# MSS_GIO register map
Vendor: Texas Instruments
Peripheral module from a debugger description file (folder awr29xx).
Registers are 32-bit, read-write, no defined reset value unless marked. A register's access mark holds for its fields unless they carry their own. Offsets are as the file gives them; lines under a group give offsets from that group; [hi:lo] are bit positions; {n}, {i} and the like mark numbered series; 'fields as' and 'values as' point back to an identical list; <NAME> marks a mode.

## MSS_GIO
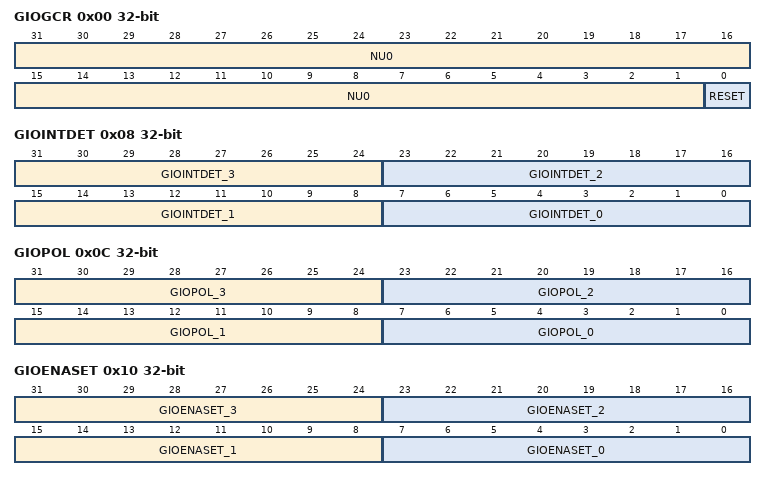
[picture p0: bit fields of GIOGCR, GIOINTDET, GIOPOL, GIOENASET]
0x00 GIOGCR — GIO reset
  [31:1] NU0 — Reserved
  [0] RESET — GIO reset
0x04 GIOPWDN 33-bit — GIO power down mode register
  [32:1] NU — Reserved
  [0] GIOPWDN — Writing to the GIOPWDN bit is only allowed in privilege mode. Reading of the GIOPWDN bit is allowed in all modes. Privilege mode (write): 0 = Normal operation; clocks enabled to GIO module 1 = Power-down mode User mode (write): Writes have no effect in user mode. User or privilege mode (read): 0 = Normal operation; clocks enabled to GIO module 1 = Power-down mode
0x08 GIOINTDET — Interrupt detection select for pins [0:1] GIO[7:0].
  [31:24] GIOINTDET_3 — Interrupt detection select for pins GIOD[7:0].
  [23:16] GIOINTDET_2 — Interrupt detection select for pins GIOC[7:0].
  [15:8] GIOINTDET_1 — Interrupt detection select for pins GIOB[7:0].
  [7:0] GIOINTDET_0 — Interrupt detection select for pins GIOA[7:0].
0x0C GIOPOL — Interrupt polarity select for pins [0:1] GIO[7:0].
  [31:24] GIOPOL_3 — Interrupt polarity select for pins GIOD[7:0]
  [23:16] GIOPOL_2 — Interrupt polarity select for pins GIOC[7:0]
  [15:8] GIOPOL_1 — Interrupt polarity select for pins GIOB[7:0]
  [7:0] GIOPOL_0 — Interrupt polarity select for pins GIOA[7:0]
0x10 GIOENASET — Interrupt enable for pins [0:1] GIO[7:0].
  [31:24] GIOENASET_3 — Interrupt enable for pins GIOD [7:0]
  [23:16] GIOENASET_2 — Interrupt enable for pins GIOC [7:0]
  [15:8] GIOENASET_1 — Interrupt enable for pins GIOB [7:0]
  [7:0] GIOENASET_0 — Interrupt enable for pins GIOA [7:0]
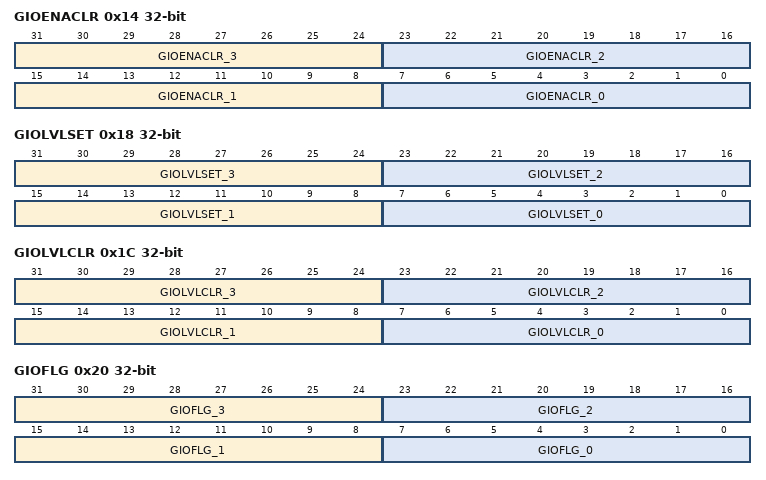
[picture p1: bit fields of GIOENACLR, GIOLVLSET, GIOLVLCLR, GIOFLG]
0x14 GIOENACLR — Interrupt enable for pins [0:1] GIO[7:0].
  [31:24] GIOENACLR_3 — Interrupt enable for pins GIOD [7:0]
  [23:16] GIOENACLR_2 — Interrupt enable for pins GIOC [7:0]
  [15:8] GIOENACLR_1 — Interrupt enable for pins GIOB [7:0]
  [7:0] GIOENACLR_0 — Interrupt enable for pins GIOA [7:0]
0x18 GIOLVLSET — GIO high priority interrupt for pins [0:1] GIO[7:0].
  [31:24] GIOLVLSET_3 — GIO high priority interrupt for pins GIOD[7:0]
  [23:16] GIOLVLSET_2 — GIO high priority interrupt for pins GIOC[7:0]
  [15:8] GIOLVLSET_1 — GIO high priority interrupt for pins GIOB[7:0]
  [7:0] GIOLVLSET_0 — GIO high priority interrupt for pins GIOA[7:0]
0x1C GIOLVLCLR — GIO low priority interrupt for pins [0:1] GIO[7:0].
  [31:24] GIOLVLCLR_3 — GIO low priority interrupt for pins GIOD[7:0]
  [23:16] GIOLVLCLR_2 — GIO low priority interrupt for pins GIOC[7:0]
  [15:8] GIOLVLCLR_1 — GIO low priority interrupt for pins GIOB[7:0]
  [7:0] GIOLVLCLR_0 — GIO low priority interrupt for pins GIOA[7:0]
0x20 GIOFLG — GIO flag for pins [0:1] GIO[7:0].
  [31:24] GIOFLG_3 — GIO flag for pins GIOD[7:0]
  [23:16] GIOFLG_2 — GIO flag for pins GIOC[7:0]
  [15:8] GIOFLG_1 — GIO flag for pins GIOB[7:0]
  [7:0] GIOFLG_0 — GIO flag for pins GIOA[7:0]
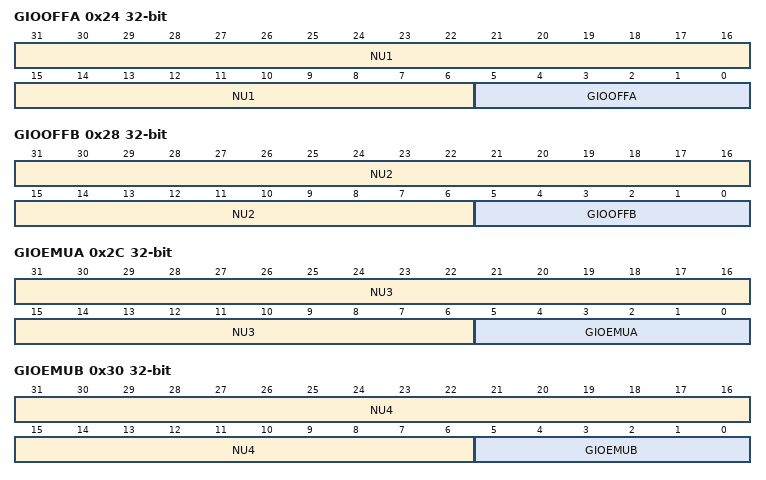
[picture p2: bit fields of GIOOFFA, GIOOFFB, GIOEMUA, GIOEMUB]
0x24 GIOOFFA — Index bits for currently pending high-priority interrupt Register A
  [31:6] NU1 — Reserved
  [5:0] GIOOFFA — Index bits for currently pending high-priority interrupt Register A
0x28 GIOOFFB — Index bits for currently pending high-priority interrupt Register B
  [31:6] NU2 — Reserved
  [5:0] GIOOFFB — Index bits for currently pending high-priority interrupt Register B
0x2C GIOEMUA — GIO emulation register A
  [31:6] NU3 — Reserved
  [5:0] GIOEMUA — GIO emulation register A
0x30 GIOEMUB — GIO emulation register B
  [31:6] NU4 — Reserved
  [5:0] GIOEMUB — GIO emulation register B
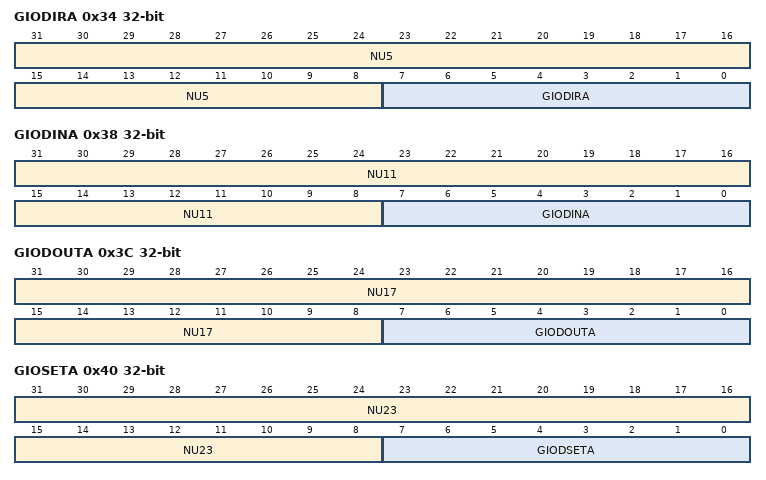
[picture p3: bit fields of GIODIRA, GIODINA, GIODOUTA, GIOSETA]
0x34 GIODIRA — GIO data direction of pins in Port A
  [31:8] NU5 — Reserved
  [7:0] GIODIRA — GIO data direction of pins in Port A
0x38 GIODINA — GIO data input for pins in port A
  [31:8] NU11 — Reserved
  [7:0] GIODINA — GIO data input for pins in port A
0x3C GIODOUTA — GIO data output for pins in port A
  [31:8] NU17 — Reserved
  [7:0] GIODOUTA — GIO data output for pins in port A
0x40 GIOSETA — GIO data set for port A
  [31:8] NU23 — Reserved
  [7:0] GIODSETA — GIO data set for port A
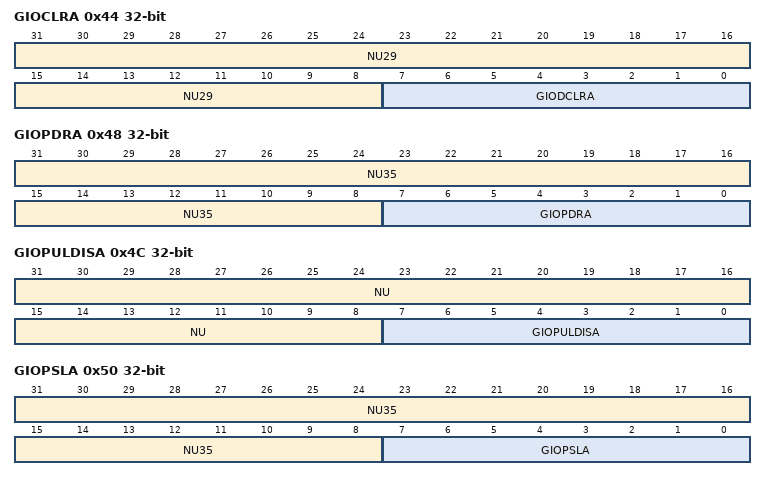
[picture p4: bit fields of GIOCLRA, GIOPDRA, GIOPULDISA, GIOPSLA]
0x44 GIOCLRA — GIO data clear for port A
  [31:8] NU29 — Reserved
  [7:0] GIODCLRA — GIO data clear for port A
0x48 GIOPDRA — GIO open drain for port A
  [31:8] NU35 — Reserved
  [7:0] GIOPDRA — GIO open drain for port A
0x4C GIOPULDISA — GIO pul disable for port A
  [31:8] NU — Reserved
  [7:0] GIOPULDISA — GIO pull disable for port A
0x50 GIOPSLA — GIO pul select for port A
  [31:8] NU35 — Reserved
  [7:0] GIOPSLA — GIO pull select for port A
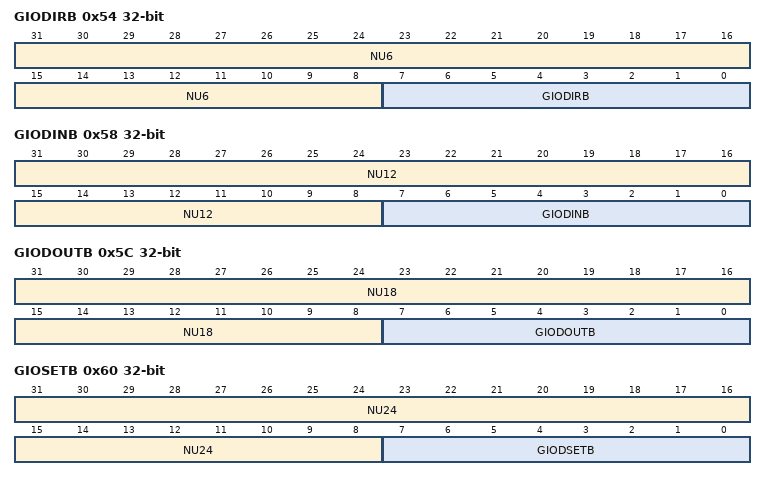
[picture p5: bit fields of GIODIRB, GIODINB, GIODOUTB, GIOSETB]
0x54 GIODIRB — GIO data direction of pins in Port B
  [31:8] NU6 — Reserved
  [7:0] GIODIRB — GIO data direction of pins in Port B
0x58 GIODINB — GIO data input for pins in port B
  [31:8] NU12 — Reserved
  [7:0] GIODINB — GIO data input for pins in port B
0x5C GIODOUTB — GIO data output for pins in port B
  [31:8] NU18 — Reserved
  [7:0] GIODOUTB — GIO data output for pins in port B
0x60 GIOSETB — GIO data set for port B
  [31:8] NU24 — Reserved
  [7:0] GIODSETB — GIO data set for port B
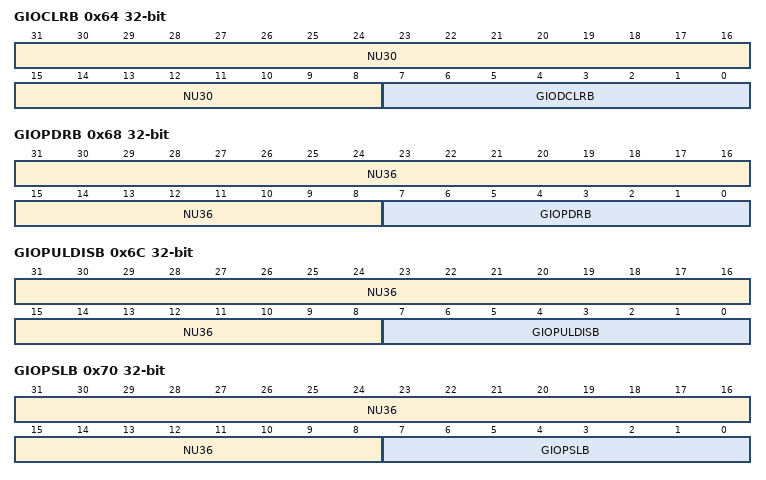
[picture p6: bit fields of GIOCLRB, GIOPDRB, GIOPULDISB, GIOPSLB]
0x64 GIOCLRB — GIO data clear for port B
  [31:8] NU30 — Reserved
  [7:0] GIODCLRB — GIO data clear for port B
0x68 GIOPDRB — GIO open drain for port B
  [31:8] NU36 — Reserved
  [7:0] GIOPDRB — GIO open drain for port B
0x6C GIOPULDISB — GIO pul disable for port B
  [31:8] NU36 — Reserved
  [7:0] GIOPULDISB — GIO pull disable for port B
0x70 GIOPSLB — GIO pul select for port B
  [31:8] NU36 — Reserved
  [7:0] GIOPSLB — GIO pull select for port B
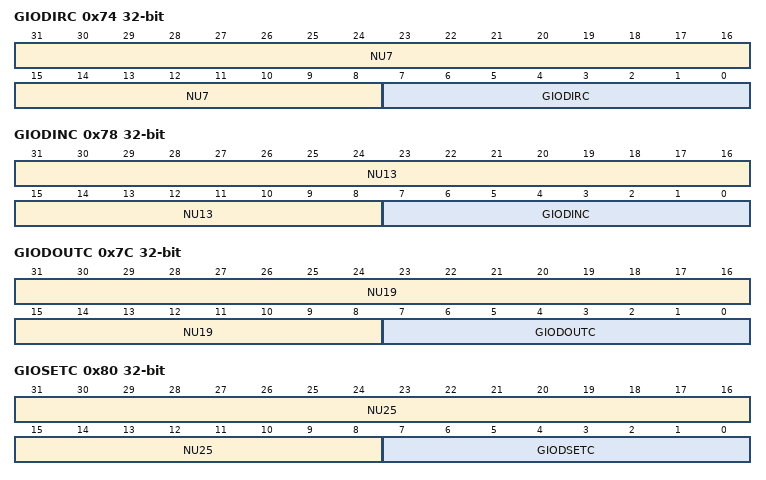
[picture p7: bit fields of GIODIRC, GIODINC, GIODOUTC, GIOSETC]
0x74 GIODIRC — GIO data direction of pins in Port C
  [31:8] NU7 — Reserved
  [7:0] GIODIRC — GIO data direction of pins in Port C
0x78 GIODINC — GIO data input for pins in port C
  [31:8] NU13 — Reserved
  [7:0] GIODINC — GIO data input for pins in port C
0x7C GIODOUTC — GIO data output for pins in port C
  [31:8] NU19 — Reserved
  [7:0] GIODOUTC — GIO data output for pins in port C
0x80 GIOSETC — GIO data set for port C
  [31:8] NU25 — Reserved
  [7:0] GIODSETC — GIO data set for port C
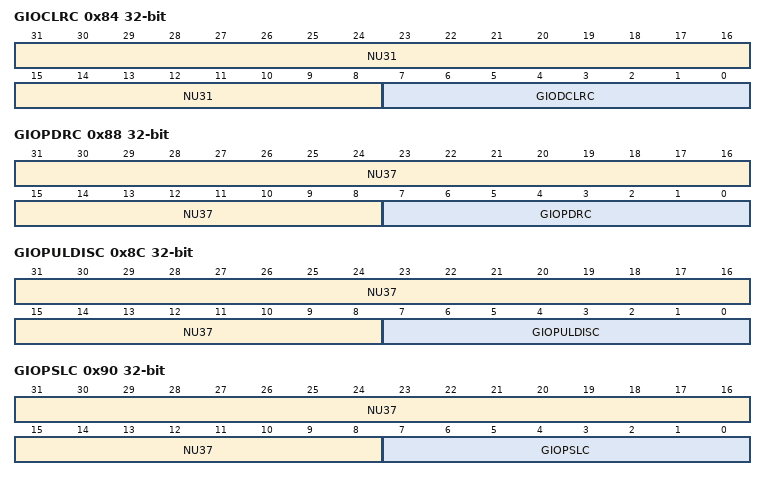
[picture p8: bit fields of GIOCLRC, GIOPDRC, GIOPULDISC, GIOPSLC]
0x84 GIOCLRC — GIO data clear for port C
  [31:8] NU31 — Reserved
  [7:0] GIODCLRC — GIO data clear for port C
0x88 GIOPDRC — GIO open drain for port C
  [31:8] NU37 — Reserved
  [7:0] GIOPDRC — GIO open drain for port C
0x8C GIOPULDISC — GIO pul disable for port C
  [31:8] NU37 — Reserved
  [7:0] GIOPULDISC — GIO pull disable for port C
0x90 GIOPSLC — GIO pul select for port C
  [31:8] NU37 — Reserved
  [7:0] GIOPSLC — GIO pull select for port C
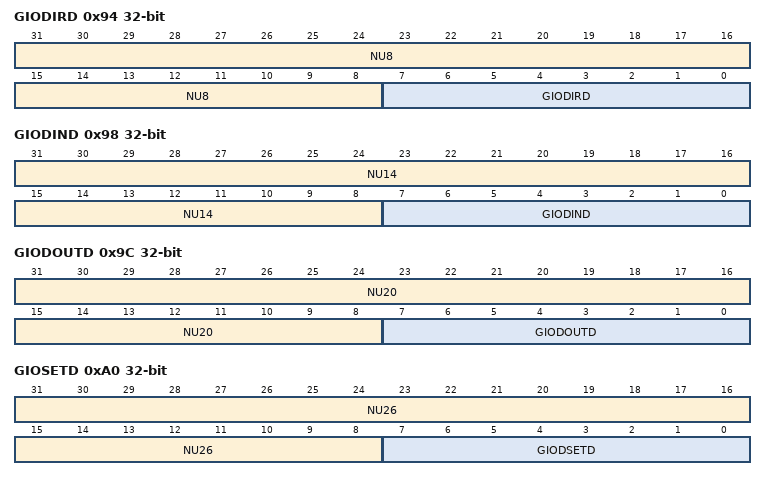
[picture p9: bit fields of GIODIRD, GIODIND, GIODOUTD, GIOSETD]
0x94 GIODIRD — GIO data direction of pins in Port D
  [31:8] NU8 — Reserved
  [7:0] GIODIRD — GIO data direction of pins in Port D
0x98 GIODIND — GIO data input for pins in port D
  [31:8] NU14 — Reserved
  [7:0] GIODIND — GIO data input for pins in port D
0x9C GIODOUTD — GIO data output for pins in port D
  [31:8] NU20 — Reserved
  [7:0] GIODOUTD — GIO data output for pins in port D
0xA0 GIOSETD — GIO data set for port D
  [31:8] NU26 — Reserved
  [7:0] GIODSETD — GIO data set for port D
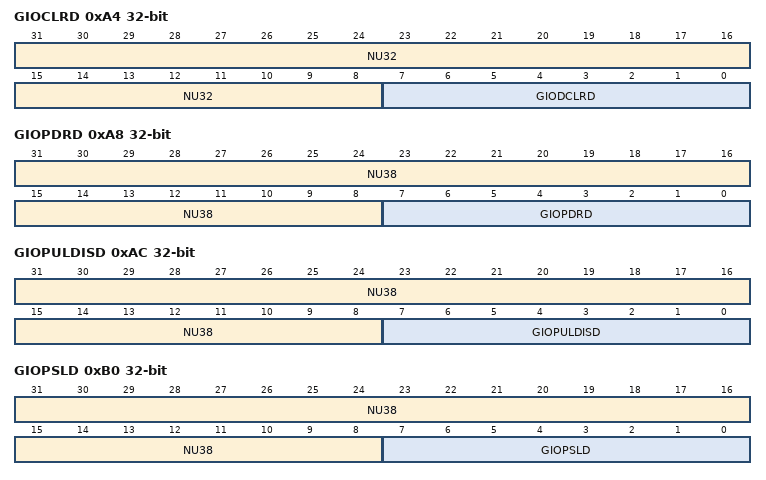
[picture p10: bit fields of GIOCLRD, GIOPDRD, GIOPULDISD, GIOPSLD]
0xA4 GIOCLRD — GIO data clear for port D
  [31:8] NU32 — Reserved
  [7:0] GIODCLRD — GIO data clear for port D
0xA8 GIOPDRD — GIO open drain for port D
  [31:8] NU38 — Reserved
  [7:0] GIOPDRD — GIO open drain for port D
0xAC GIOPULDISD — GIO pul disable for port D
  [31:8] NU38 — Reserved
  [7:0] GIOPULDISD — GIO pull disable for port D
0xB0 GIOPSLD — GIO pul select for port D
  [31:8] NU38 — Reserved
  [7:0] GIOPSLD — GIO pull select for port D
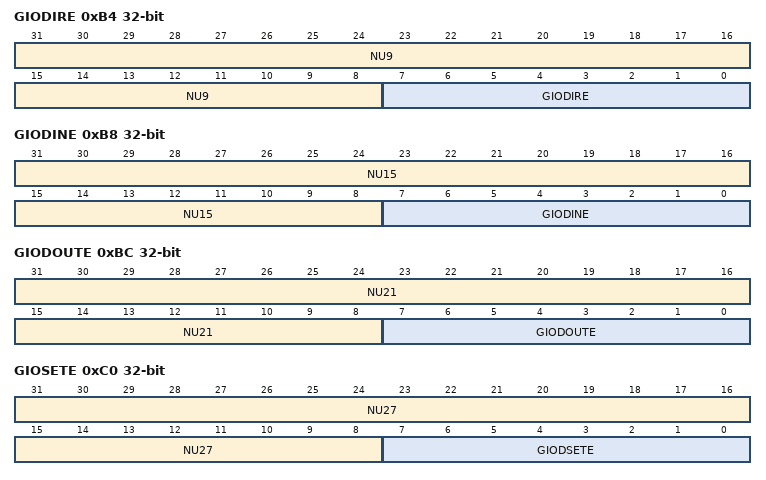
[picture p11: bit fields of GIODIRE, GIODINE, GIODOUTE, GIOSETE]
0xB4 GIODIRE — GIO data direction of pins in Port E
  [31:8] NU9 — Reserved
  [7:0] GIODIRE — GIO data direction of pins in Port E
0xB8 GIODINE — GIO data input for pins in port E
  [31:8] NU15 — Reserved
  [7:0] GIODINE — GIO data input for pins in port E
0xBC GIODOUTE — GIO data output for pins in port E
  [31:8] NU21 — Reserved
  [7:0] GIODOUTE — GIO data output for pins in port E
0xC0 GIOSETE — GIO data set for port E
  [31:8] NU27 — Reserved
  [7:0] GIODSETE — GIO data set for port E
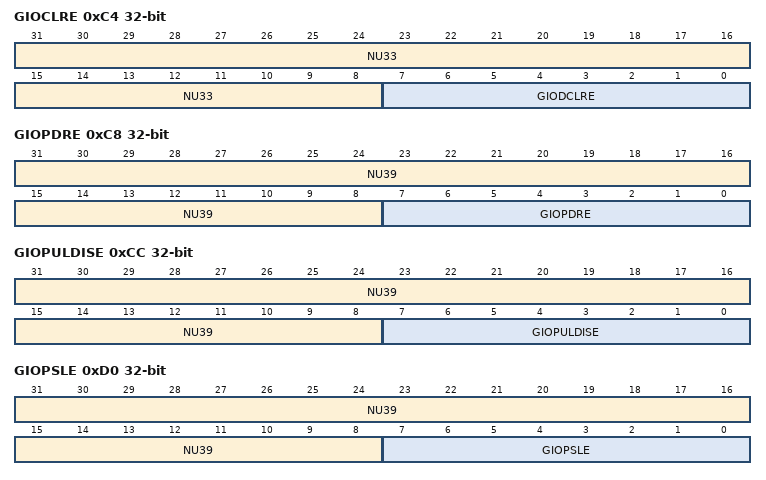
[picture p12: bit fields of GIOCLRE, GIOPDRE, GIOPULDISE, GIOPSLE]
0xC4 GIOCLRE — GIO data clear for port E
  [31:8] NU33 — Reserved
  [7:0] GIODCLRE — GIO data clear for port E
0xC8 GIOPDRE — GIO open drain for port E
  [31:8] NU39 — Reserved
  [7:0] GIOPDRE — GIO open drain for port E
0xCC GIOPULDISE — GIO pul disable for port E
  [31:8] NU39 — Reserved
  [7:0] GIOPULDISE — GIO pull disable for port E
0xD0 GIOPSLE — GIO pul select for port E
  [31:8] NU39 — Reserved
  [7:0] GIOPSLE — GIO pull select for port E
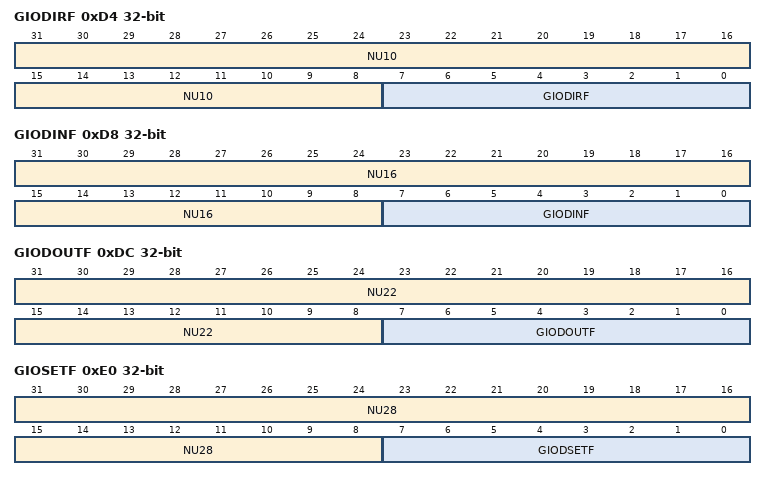
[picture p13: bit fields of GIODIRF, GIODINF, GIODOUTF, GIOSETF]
0xD4 GIODIRF — GIO data direction of pins in Port F
  [31:8] NU10 — Reserved
  [7:0] GIODIRF — GIO data direction of pins in Port F
0xD8 GIODINF — GIO data input for pins in Port F
  [31:8] NU16 — Reserved
  [7:0] GIODINF — GIO data input for pins in port F
0xDC GIODOUTF — GIO data output for pins in Port F
  [31:8] NU22 — Reserved
  [7:0] GIODOUTF — GIO data output for pins in port F
0xE0 GIOSETF — GIO data set for Port F
  [31:8] NU28 — Reserved
  [7:0] GIODSETF — GIO data set for port F
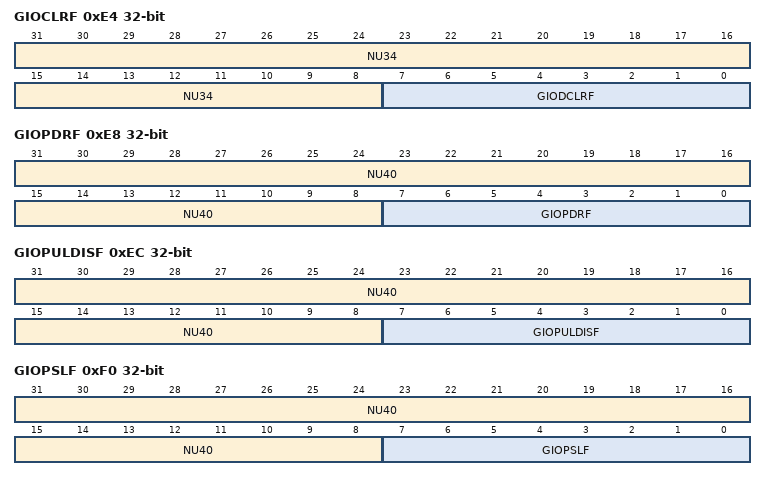
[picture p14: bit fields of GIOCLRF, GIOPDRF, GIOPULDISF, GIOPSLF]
0xE4 GIOCLRF — GIO data clear for Port F
  [31:8] NU34 — Reserved
  [7:0] GIODCLRF — GIO data clear for port F
0xE8 GIOPDRF — GIO open drain for Port F
  [31:8] NU40 — Reserved
  [7:0] GIOPDRF — GIO open drain for port F
0xEC GIOPULDISF — GIO pul disable for port F
  [31:8] NU40 — Reserved
  [7:0] GIOPULDISF — GIO pull disable for port F
0xF0 GIOPSLF — GIO pul select for port F
  [31:8] NU40 — Reserved
  [7:0] GIOPSLF — GIO pull select for port F
0xF4 GIODIRG — GIO data direction of pins in Port G
  [31:8] NU9 — Reserved
  [7:0] GIODIRG — GIO data direction of pins in Port G
0xF8 GIODING — GIO data input for pins in port G
  [31:8] NU15 — Reserved
  [7:0] GIODING — GIO data input for pins in port G
0xFC GIODOUTG — GIO data output for pins in port G
  [31:8] NU21 — Reserved
  [7:0] GIODOUTG — GIO data output for pins in port G
0x100 GIOSETG — GIO data set for port G
  [31:8] NU27 — Reserved
  [7:0] GIODSETG — GIO data set for port G
0x104 GIOCLRG — GIO data clear for port G
  [31:8] NU33 — Reserved
  [7:0] GIODCLRG — GIO data clear for port G
0x108 GIOPDRG — GIO open drain for port G
  [31:8] NU39 — Reserved
  [7:0] GIOPDRG — GIO open drain for port G
0x10C GIOPULDISG — GIO pul disable for port G
  [31:8] NU39 — Reserved
  [7:0] GIOPULDISG — GIO pull disable for port G
0x110 GIOPSLG — GIO pul select for port G
  [31:8] NU39 — Reserved
  [7:0] GIOPSLG — GIO pull select for port G
0x114 GIODIRH — GIO data direction of pins in Port H
  [31:8] NU10 — Reserved
  [7:0] GIODIRH — GIO data direction of pins in Port H
0x118 GIODINH — GIO data input for pins in Port H
  [31:8] NU16 — Reserved
  [7:0] GIODINH — GIO data input for pins in port H
0x11C GIODOUTH — GIO data output for pins in Port H
  [31:8] NU22 — Reserved
  [7:0] GIODOUTH — GIO data output for pins in port H
0x120 GIOSETH — GIO data set for Port H
  [31:8] NU28 — Reserved
  [7:0] GIODSETH — GIO data set for port H
0x124 GIOCLRH — GIO data clear for Port H
  [31:8] NU34 — Reserved
  [7:0] GIODCLRH — GIO data clear for port H
0x128 GIOPDRH — GIO open drain for Port H
  [31:8] NU40 — Reserved
  [7:0] GIOPDRH — GIO open drain for port H
0x12C GIOPULDISH — GIO pul disable for port H
  [31:8] NU40 — Reserved
  [7:0] GIOPULDISH — GIO pull disable for port H
0x130 GIOPSLH — GIO pul select for port H
  [31:8] NU40 — Reserved
  [7:0] GIOPSLH — GIO pull select for port H
0x134 GIOSRCA — GIO slew rate select for port A
  [31:8] NU35 — Reserved
  [7:0] GIOSRCA — GIO slew rate control for port A
0x138 GIOSRCB — GIO slew rate select for port B
  [31:8] NU36 — Reserved
  [7:0] GIOSRCB — GIO slew rate control for port B
0x13C GIOSRCC — GIO slew rate select for port C
  [31:8] NU37 — Reserved
  [7:0] GIOSRCC — GIO slew rate control for port C
0x140 GIOSRCD — GIO slew rate select for port D
  [31:8] NU38 — Reserved
  [7:0] GIOSRCD — GIO slew rate control for port D
0x144 GIOSRCE — GIO slew rate select for port E
  [31:8] NU39 — Reserved
  [7:0] GIOSRCE — GIO slew rate control for port E
0x148 GIOSRCF — GIO slew rate select for port F
  [31:8] NU40 — Reserved
  [7:0] GIOSRCF — GIO slew rate control for port F
0x14C GIOSRCG — GIO slew rate select for port G
  [31:8] NU39 — Reserved
  [7:0] GIOSRCG — GIO slew rate control for port G
0x150 GIOSRCH — GIO slew rate select for port H
  [31:8] NU40 — Reserved
  [7:0] GIOSRCH — GIO slew rate control for port H
